# STM32H563 register map
File version: 1.8
CPU: CM33 r0p0, little endian, MPU, FPU, 4 interrupt priority bits
Registers are 32-bit, read-write, reset 0x0 unless marked. A register's access mark holds for its fields unless they carry their own. Offsets are from the block's base; [hi:lo] are bit positions.

## ADCC — ADC common registers block
Base 0x42028300
Same registers: SEC_ADCC 0x52028300
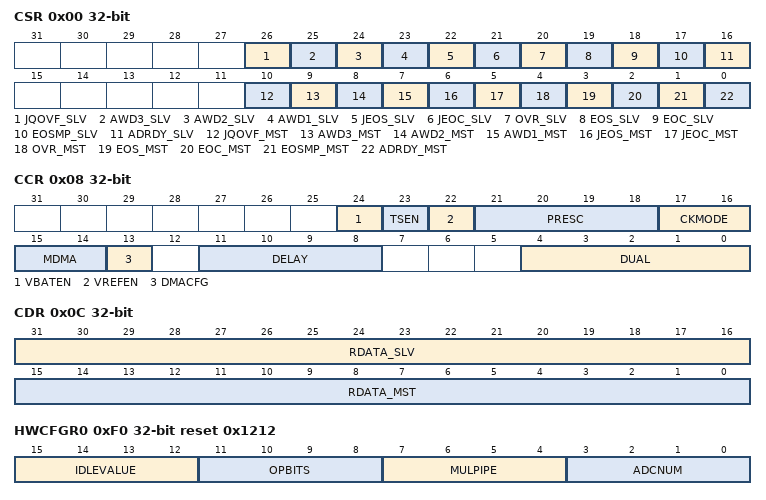
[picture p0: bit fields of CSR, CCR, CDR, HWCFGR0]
0x00 CSR ro — ADC common status register
  [26] JQOVF_SLV — Injected Context Queue Overflow flag of the slave ADC
  [25] AWD3_SLV — Analog watchdog 3 flag of the slave ADC
  [24] AWD2_SLV — Analog watchdog 2 flag of the slave ADC
  [23] AWD1_SLV — Analog watchdog 1 flag of the slave ADC
  [22] JEOS_SLV — End of injected sequence flag of the slave ADC
  [21] JEOC_SLV — End of injected conversion flag of the slave ADC
  [20] OVR_SLV — Overrun flag of the slave ADC
  [19] EOS_SLV — End of regular sequence flag of the slave ADC.
  [18] EOC_SLV — End of regular conversion of the slave ADC
  [17] EOSMP_SLV — End of Sampling phase flag of the slave ADC
  [16] ADRDY_SLV — Slave ADC ready
  [10] JQOVF_MST — Injected Context Queue Overflow flag of the master ADC
  [9] AWD3_MST — Analog watchdog 3 flag of the master ADC
  [8] AWD2_MST — Analog watchdog 2 flag of the master ADC
  [7] AWD1_MST — Analog watchdog 1 flag of the master ADC
  [6] JEOS_MST — End of injected sequence flag of the master ADC
  [5] JEOC_MST — End of injected conversion flag of the master ADC
  [4] OVR_MST — Overrun flag of the master ADC
  [3] EOS_MST — End of regular sequence flag of the master ADC
  [2] EOC_MST — End of regular conversion of the master ADC
  [1] EOSMP_MST — End of Sampling phase flag of the master ADC
  [0] ADRDY_MST — Master ADC ready
0x08 CCR — ADC common control register
  [24] VBATEN — VBAT enable
  [23] TSEN — Vless thansub>SENSEless than/sub> enable
  [22] VREFEN — Vless thansub>REFINTless than/sub> enable
  [21:18] PRESC — ADC prescaler
  [17:16] CKMODE — ADC clock mode
  [15:14] MDMA — Direct memory access mode for dual ADC mode
  [13] DMACFG — DMA configuration (for dual ADC mode)
  [11:8] DELAY — Delay between 2 sampling phases
  [4:0] DUAL — Dual ADC mode selection
0x0C CDR ro — ADC common regular data register for dual mode
  [31:16] RDATA_SLV — Regular data of the slave ADC
  [15:0] RDATA_MST — Regular data of the master ADC.
0xF0 HWCFGR0 ro reset 0x1212 — ADC hardware configuration register
  [15:12] IDLEVALUE — Idle value for non-selected channels
  [11:8] OPBITS — Number of option bits
  [7:4] MULPIPE — Number of pipeline stages
  [3:0] ADCNUM — Number of ADCs implemented
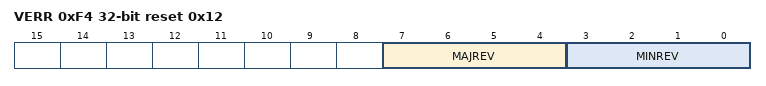
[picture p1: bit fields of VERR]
0xF4 VERR ro reset 0x12 — ADC version register
  [7:4] MAJREV — Major revision
  [3:0] MINREV — Minor revision
0xF8 IPDR ro reset 0x110006 — ADC identification register
  [31:0] ID — Peripheral identifier
0xFC SIDR ro reset 0xA3C5DD01 — ADC size identification register
  [31:0] SID — Size Identification

## CRC — Cyclic redundancy check calculation unit
Base 0x40023000
Same registers: SEC_CRC 0x50023000
0x00 DR reset 0xFFFFFFFF — CRC data register
  [31:0] DR — Data register bits This register is used to write new data to the CRC calculator. It holds the previous CRC calculation result when it is read. If the data size is less than 32 bits, the least significant bits are used to write/read the correct value.
0x00 DR8 8-bit reset 0xFF (alternate view of DR) — Data register - byte sized
  [7:0] DR8 — Data register bits
0x00 DR16 16-bit reset 0xFFFF (alternate view of DR) — Data register - half-word sized
  [15:0] DR16 — Data register bits
0x04 IDR — CRC independent data register
  [31:0] IDR — General-purpose 32-bit data register bits
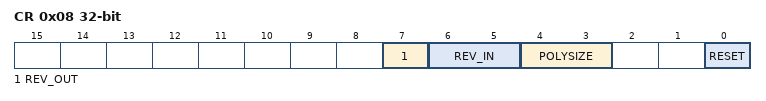
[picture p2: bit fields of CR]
0x08 CR — CRC control register
  [7] REV_OUT — Reverse output data This bit controls the reversal of the bit order of the output data.
    0=Normal (Bit order not affected); 1=Reversed (Bit reversed output)
  [6:5] REV_IN — Reverse input data These bits control the reversal of the bit order of the input data
    0=Normal (Bit order not affected); 1=Byte (Bit reversal done by byte); 2=HalfWord (Bit reversal done by half-word); 3=Word (Bit reversal done by word)
  [4:3] POLYSIZE — Polynomial size These bits control the size of the polynomial.
    0=32-bit polynomial; 1=16-bit polynomial; 2=8-bit polynomial; 3=7-bit polynomial
  [0] RESET — RESET bit This bit is set by software to reset the CRC calculation unit and set the data register to the value stored in the CRC_INIT register. This bit can only be set, it is automatically cleared by hardware
    on write: 1=Resets the CRC calculation unit and sets the data register to 0xFFFF FFFF
0x10 INIT reset 0xFFFFFFFF — CRC initial value
  [31:0] INIT — Programmable initial CRC value This register is used to write the CRC initial value.
0x14 POL reset 0x4C11DB7 — CRC polynomial
  [31:0] POL — Programmable polynomial This register is used to write the coefficients of the polynomial to be used for CRC calculation. If the polynomial size is less than 32 bits, the least significant bits have to be used to program the correct value.
